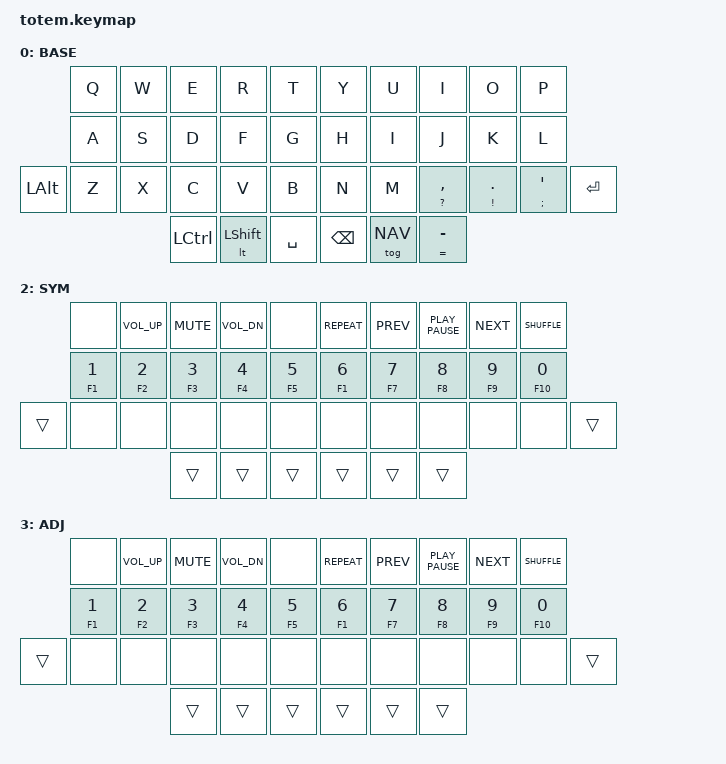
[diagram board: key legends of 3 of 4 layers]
//
//                                                        ▀▀▀▀▀     ▀▀▀▀▀          ▀▀█▀▀
//                                                        ▄▀▀▀▄  ▄  ▄▀▀▀▄  ▄  ▄▀▀▀▄  █  ▄▀▀▀▄
//                                                        █   █  █  █   █  █  █   █  █  █   █
//                                                         ▀▀▀   █   ▀▀▀   █   ▀▀▀   ▀   ▀▀▀
//                                                               █      ▄▄▄█▄▄▄    █   █  
//                                                               ▀      █  █  █     █▄█
//                                                             ▀▀▀▀▀    █  █  █      ▀
//                                                                      ▀  ▀  ▀
//
// ▄▄▄▄▄▄▄▄▄▄▄▄▄▄▄▄▄▄▄▄▄▄▄▄▄▄▄▄▄▄▄▄▄▄▄▄▄▄▄▄▄▄▄▄▄▄▄▄▄▄▄▄▄▄▄▄▄▄▄▄▄▄▄▄▄▄▄▄▄▄▄▄▄▄▄▄▄▄▄▄▄▄▄▄▄▄▄▄▄▄▄▄▄▄▄▄▄▄▄▄▄▄▄▄▄▄▄▄▄▄▄▄▄▄▄▄▄▄▄▄▄▄▄▄▄▄▄▄▄▄▄▄▄▄▄▄▄▄▄▄▄▄▄▄▄▄▄▄▄
       

#include <behaviors.dtsi>
#include <dt-bindings/zmk/keys.h>
#include <dt-bindings/zmk/bt.h>
#include <dt-bindings/zmk/outputs.h>

#define BASE 0
#define NAV  1
#define SYM  2
#define ADJ  3

&mt {
  quick-tap-ms = <100>;
  global-quick-tap;
  flavor = "tap-preferred";
  tapping-term-ms = <170>;
};

/ {
     combos {
            compatible = "zmk,combos";
            combo_esc {
                timeout-ms = <50>;
                key-positions = <0 1>;
                bindings = <&kp ESC>;
            };
            combo_tvp {
                timeout-ms = <100>;
                key-positions = <11 12 13>;
                bindings = <&tog SYM>;
            };
    };

    macros {
        gif: gif {
            label = "giphy";
            compatible = "zmk,behavior-macro";
            #binding-cells = <0>;
            bindings
                = <&macro_press &kp LSHFT>
                , <&macro_tap &kp N2>
                , <&macro_release &kp LSHFT>
                , <&macro_tap &kp G &kp I &kp F>
                ;
        };
    };

        keymap {
                compatible = "zmk,keymap";
// ▄▄▄▄▄▄▄▄▄▄▄▄▄▄▄▄▄▄▄▄▄▄▄▄▄▄▄▄▄▄▄▄▄▄▄▄▄▄▄▄▄▄▄▄▄▄▄▄▄▄▄▄▄▄▄▄▄▄▄▄▄▄▄▄▄▄▄▄▄▄▄▄▄▄▄▄▄▄▄▄▄▄▄▄▄▄▄▄▄▄▄▄▄▄▄▄▄▄▄▄▄▄▄▄▄▄▄▄▄▄▄▄▄▄▄▄▄▄▄▄▄▄▄▄▄▄▄▄▄▄▄▄▄▄▄▄▄▄▄▄▄▄▄▄▄▄▄▄▄

                base_layer {
// ┏━━━━━━━━━━━━━━━━━━━━━━━━━━━━━━━━━━━━━━━┓
label= "BASE"                              ;
// ┗━━━━━━━━━━━━━━━━━━━━━━━━━━━━━━━━━━━━━━━┛
//             ┏━━━━━━━━━━━┳━━━━━━━━━━━┳━━━━━━━━━━━┳━━━━━━━━━━━┳━━━━━━━━━━━┓   ┏━━━━━━━━━━━┳━━━━━━━━━━━┳━━━━━━━━━━━┳━━━━━━━━━━━┳━━━━━━━━━━━┓
//             ┃     Q     ┃     W     ┃     E     ┃     R     ┃     T     ┃   ┃     Y     ┃     U     ┃     I     ┃     O     ┃     P     ┃
//             ┣━━━━━━━━━━━╋━━━━━━━━━━━╋━━━━━━━━━━━╋━━━━━━━━━━━╋━━━━━━━━━━━┫   ┣━━━━━━━━━━━╋━━━━━━━━━━━╋━━━━━━━━━━━╋━━━━━━━━━━━╋━━━━━━━━━━━┫
//             ┃     A     ┃     S     ┃     D     ┃     F     ┃     G     ┃   ┃     H     ┃     I     ┃     J     ┃     K     ┃     L     ┃
// ┏━━━━━━━━━━━╋━━━━━━━━━━━╋━━━━━━━━━━━╋━━━━━━━━━━━╋━━━━━━━━━━━╋━━━━━━━━━━━┫   ┣━━━━━━━━━━━╋━━━━━━━━━━━╋━━━━━━━━━━━╋━━━━━━━━━━━╋━━━━━━━━━━━╋━━━━━━━━━━━┓
// ┃   L ALT   ┃     Z     ┃     X     ┃     C     ┃     V     ┃     B     ┃   ┃     N     ┃     M     ┃   , / ?   ┃   . / !   ┃Apos. / :   ┃   ENTER   ┃
// ┗━━━━━━━━━━━┻━━━━━━━━━━━┻━━━━━━━━━━━╋━━━━━━━━━━━╋━━━━━━━━━━━╋━━━━━━━━━━━┫   ┣━━━━━━━━━━━╋━━━━━━━━━━━╋━━━━━━━━━━━╋━━━━━━━━━━━┻━━━━━━━━━━━┻━━━━━━━━━━━┛
//                                     ┃    CTRL   ┃  L SHIFT  ┃    SPC    ┃   ┃   BSPC    ┃   L:NAV   ┃    - / =  ┃
//                                     ┗━━━━━━━━━━━┻━━━━━━━━━━━┻━━━━━━━━━━━┛   ┗━━━━━━━━━━━┻━━━━━━━━━━━┻━━━━━━━━━━━┛
 bindings = <
// ╷           ╷           ╷           ╷           ╷           ╷           ╷   ╷           ╷           ╷           ╷           ╷           ╷           ╷

                &kp Q       &kp W       &kp E       &kp R       &kp T           &kp Y       &kp U       &kp I       &kp O       &kp P
                &kp A       &kp S       &kp D       &kp F       &kp G           &kp H       &kp I       &kp J       &kp K       &kp L
    &kp LALT    &kp Z       &kp X       &kp C       &kp V       &kp B           &kp N       &kp M &mt QMARK COMMA &mt EXCL DOT &mt SEMI APOS  &kp RET
                                        &kp LCTRL   &lt LSHFT   &kp SPACE       &kp BSPC    &tog NAV    &mt EQUAL MINUS
                        >;
                };

// ▄▄▄▄▄▄▄▄▄▄▄▄▄▄▄▄▄▄▄▄▄▄▄▄▄▄▄▄▄▄▄▄▄▄▄▄▄▄▄▄▄▄▄▄▄▄▄▄▄▄▄▄▄▄▄▄▄▄▄▄▄▄▄▄▄▄▄▄▄▄▄▄▄▄▄▄▄▄▄▄▄▄▄▄▄▄▄▄▄▄▄▄▄▄▄▄▄▄▄▄▄▄▄▄▄▄▄▄▄▄▄▄▄▄▄▄▄▄▄▄▄▄▄▄▄▄▄▄▄▄▄▄▄▄▄▄▄▄▄▄▄▄▄▄▄▄▄▄▄


                nav_layer {
// ┏━━━━━━━━━━━━━━━━━━━━━━━━━━━━━━━━━━━━━━━┓
label= "NAVI"                              ;
// ┗━━━━━━━━━━━━━━━━━━━━━━━━━━━━━━━━━━━━━━━┛
//             ┏━━━━━━━━━━━┳━━━━━━━━━━━┳━━━━━━━━━━━┳━━━━━━━━━━━┳━━━━━━━━━━━┓   ┏━━━━━━━━━━━┳━━━━━━━━━━━┳━━━━━━━━━━━┳━━━━━━━━━━━┳━━━━━━━━━━━┓
//             ┃    ESC    ┃   P UP    ┃     UP    ┃   P DOWN  ┃   LBrac   ┃   ┃   RBrac   ┃     7     ┃     8     ┃     9     ┃     +     ┃
//             ┣━━━━━━━━━━━╋━━━━━━━━━━━╋━━━━━━━━━━━╋━━━━━━━━━━━╋━━━━━━━━━━━┫   ┣━━━━━━━━━━━╋━━━━━━━━━━━╋━━━━━━━━━━━╋━━━━━━━━━━━╋━━━━━━━━━━━┫
//             ┃    CAPS   ┃   LEFT    ┃    DOWN   ┃   RIGHT   ┃   LPare   ┃   ┃   RPare   ┃     4     ┃     5     ┃     6     ┃     -     ┃
// ┏━━━━━━━━━━━╋━━━━━━━━━━━╋━━━━━━━━━━━╋━━━━━━━━━━━╋━━━━━━━━━━━╋━━━━━━━━━━━┫   ┣━━━━━━━━━━━╋━━━━━━━━━━━╋━━━━━━━━━━━╋━━━━━━━━━━━╋━━━━━━━━━━━╋━━━━━━━━━━━┓
// ┃    ===    ┃    TAB    ┃           ┃           ┃     /     ┃     \     ┃   ┃     0     ┃     1     ┃     2     ┃     3     ┃     *     ┃    ===    ┃
// ┗━━━━━━━━━━━┻━━━━━━━━━━━┻━━━━━━━━━━━╋━━━━━━━━━━━╋━━━━━━━━━━━╋━━━━━━━━━━━┫   ┣━━━━━━━━━━━╋━━━━━━━━━━━╋━━━━━━━━━━━╋━━━━━━━━━━━┻━━━━━━━━━━━┻━━━━━━━━━━━┛
//                                     ┃    ===    ┃    ===    ┃    ===    ┃   ┃   ===     ┃    ===    ┃    DEL    ┃
//                                     ┗━━━━━━━━━━━┻━━━━━━━━━━━┻━━━━━━━━━━━┛   ┗━━━━━━━━━━━┻━━━━━━━━━━━┻━━━━━━━━━━━┛
 bindings = <
// ╷           ╷           ╷           ╷           ╷           ╷           ╷   ╷           ╷           ╷           ╷           ╷           ╷           ╷

                &kp ESC     &kp PG_UP   &kp UP      &kp PG_DN   &kp LBKT        &kp RBKT    &kp KP_N7   &kp KP_N8   &kp KP_N9   &kp KP_PLUS
                &kp CAPS    &kp LEFT    &kp DOWN    &kp RIGHT &mt LBRC LPAR   &kp RBRC RPAR &kp KP_N4   &kp KP_N5   &kp KP_N6   &kp KP_MINUS
    &trans      &kp TAB     &none       &none       &kp FSLH    &kp BSLH        &kp KP_N0   &kp KP_N1   &kp KP_N2   &kp KP_N3 &kp KP_MULTIPLY &trans      
                                        &trans      &trans      &trans          &trans      &trans      &DEL      
                        >;
                };

// ▄▄▄▄▄▄▄▄▄▄▄▄▄▄▄▄▄▄▄▄▄▄▄▄▄▄▄▄▄▄▄▄▄▄▄▄▄▄▄▄▄▄▄▄▄▄▄▄▄▄▄▄▄▄▄▄▄▄▄▄▄▄▄▄▄▄▄▄▄▄▄▄▄▄▄▄▄▄▄▄▄▄▄▄▄▄▄▄▄▄▄▄▄▄▄▄▄▄▄▄▄▄▄▄▄▄▄▄▄▄▄▄▄▄▄▄▄▄▄▄▄▄▄▄▄▄▄▄▄▄▄▄▄▄▄▄▄▄▄▄▄▄▄▄▄▄▄▄▄


                sim_layer {
// ┏━━━━━━━━━━━━━━━━━━━━━━━━━━━━━━━━━━━━━━━┓
label= "SYM"                               ;
// ┗━━━━━━━━━━━━━━━━━━━━━━━━━━━━━━━━━━━━━━━┛
//             ┏━━━━━━━━━━━┳━━━━━━━━━━━┳━━━━━━━━━━━┳━━━━━━━━━━━┳━━━━━━━━━━━┓   ┏━━━━━━━━━━━┳━━━━━━━━━━━┳━━━━━━━━━━━┳━━━━━━━━━━━┳━━━━━━━━━━━┓
//             ┃           ┃   VOL UP  ┃    MUTE   ┃ VOL DOWN  ┃           ┃   ┃  REPEAT   ┃   PREV    ┃ PLAY/PAU. ┃    NEXT   ┃  SHUFFLE  ┃
//             ┣━━━━━━━━━━━╋━━━━━━━━━━━╋━━━━━━━━━━━╋━━━━━━━━━━━╋━━━━━━━━━━━┫   ┣━━━━━━━━━━━╋━━━━━━━━━━━╋━━━━━━━━━━━╋━━━━━━━━━━━╋━━━━━━━━━━━┫
//             ┃   1 / F1  ┃   2 / F2  ┃   3 / F3  ┃   4 / F4  ┃   5 / F5  ┃   ┃   6 / F6  ┃   7 / F7  ┃   8 / F8  ┃   9 / F9  ┃  0 / F10  ┃
// ┏━━━━━━━━━━━╋━━━━━━━━━━━╋━━━━━━━━━━━╋━━━━━━━━━━━╋━━━━━━━━━━━╋━━━━━━━━━━━┫   ┣━━━━━━━━━━━╋━━━━━━━━━━━╋━━━━━━━━━━━╋━━━━━━━━━━━╋━━━━━━━━━━━╋━━━━━━━━━━━┓
// ┃    ===    ┃           ┃           ┃           ┃           ┃           ┃   ┃           ┃           ┃           ┃           ┃           ┃           ┃
// ┗━━━━━━━━━━━┻━━━━━━━━━━━┻━━━━━━━━━━━╋━━━━━━━━━━━╋━━━━━━━━━━━╋━━━━━━━━━━━┫   ┣━━━━━━━━━━━╋━━━━━━━━━━━╋━━━━━━━━━━━╋━━━━━━━━━━━┻━━━━━━━━━━━┻━━━━━━━━━━━┛
//                                     ┃    ===    ┃    ===    ┃    ===    ┃   ┃    ===    ┃    ===    ┃    ===    ┃
//                                     ┗━━━━━━━━━━━┻━━━━━━━━━━━┻━━━━━━━━━━━┛   ┗━━━━━━━━━━━┻━━━━━━━━━━━┻━━━━━━━━━━━┛
 bindings = <
// ╷           ╷           ╷           ╷           ╷           ╷           ╷   ╷           ╷           ╷           ╷           ╷           ╷           ╷

                &none     &kp K_VOL_UP  &kp K_MUTE &kp K_VOL_DN &none           &kp C_REPEAT       &kp K_PREV &kp K_PLAY_PAUSE &kp K_NEXT   &kp C_SHUFFLE
                &mt F1 N1   &mt F2 N2   &mt F3 N3   &mt F4 N4   &mt F5 N5       &mt F1 N6   &mt F7 N7   &mt F8 N8   &mt F9 N9   &mt F10 N0
    &trans      &none       &none       &none       &none       &none           &none       &none       &none       &none       &none       &trans        
                                        &trans      &trans      &trans          &trans      &trans      &trans    
                        >;
                };

// ▄▄▄▄▄▄▄▄▄▄▄▄▄▄▄▄▄▄▄▄▄▄▄▄▄▄▄▄▄▄▄▄▄▄▄▄▄▄▄▄▄▄▄▄▄▄▄▄▄▄▄▄▄▄▄▄▄▄▄▄▄▄▄▄▄▄▄▄▄▄▄▄▄▄▄▄▄▄▄▄▄▄▄▄▄▄▄▄▄▄▄▄▄▄▄▄▄▄▄▄▄▄▄▄▄▄▄▄▄▄▄▄▄▄▄▄▄▄▄▄▄▄▄▄▄▄▄▄▄▄▄▄▄▄▄▄▄▄▄▄▄▄▄▄▄▄▄▄▄


                adjust_layer {
// ┏━━━━━━━━━━━━━━━━━━━━━━━━━━━━━━━━━━━━━━━┓
label= "ADJ"                               ;
// ┗━━━━━━━━━━━━━━━━━━━━━━━━━━━━━━━━━━━━━━━┛
//             ┏━━━━━━━━━━━┳━━━━━━━━━━━┳━━━━━━━━━━━┳━━━━━━━━━━━┳━━━━━━━━━━━┓   ┏━━━━━━━━━━━┳━━━━━━━━━━━┳━━━━━━━━━━━┳━━━━━━━━━━━┳━━━━━━━━━━━┓
//             ┃           ┃   VOL UP  ┃    MUTE   ┃ VOL DOWN  ┃           ┃   ┃  REPEAT   ┃   PREV    ┃ PLAY/PAU. ┃    NEXT   ┃  SHUFFLE  ┃
//             ┣━━━━━━━━━━━╋━━━━━━━━━━━╋━━━━━━━━━━━╋━━━━━━━━━━━╋━━━━━━━━━━━┫   ┣━━━━━━━━━━━╋━━━━━━━━━━━╋━━━━━━━━━━━╋━━━━━━━━━━━╋━━━━━━━━━━━┫
//             ┃   1 / F1  ┃   2 / F2  ┃   3 / F3  ┃   4 / F4  ┃   5 / F5  ┃   ┃   6 / F6  ┃   7 / F7  ┃   8 / F8  ┃   9 / F9  ┃  0 / F10  ┃
// ┏━━━━━━━━━━━╋━━━━━━━━━━━╋━━━━━━━━━━━╋━━━━━━━━━━━╋━━━━━━━━━━━╋━━━━━━━━━━━┫   ┣━━━━━━━━━━━╋━━━━━━━━━━━╋━━━━━━━━━━━╋━━━━━━━━━━━╋━━━━━━━━━━━╋━━━━━━━━━━━┓
// ┃    ===    ┃           ┃           ┃           ┃           ┃           ┃   ┃           ┃           ┃           ┃           ┃           ┃           ┃
// ┗━━━━━━━━━━━┻━━━━━━━━━━━┻━━━━━━━━━━━╋━━━━━━━━━━━╋━━━━━━━━━━━╋━━━━━━━━━━━┫   ┣━━━━━━━━━━━╋━━━━━━━━━━━╋━━━━━━━━━━━╋━━━━━━━━━━━┻━━━━━━━━━━━┻━━━━━━━━━━━┛
//                                     ┃    ===    ┃    ===    ┃    ===    ┃   ┃    ===    ┃    ===    ┃    ===    ┃
//                                     ┗━━━━━━━━━━━┻━━━━━━━━━━━┻━━━━━━━━━━━┛   ┗━━━━━━━━━━━┻━━━━━━━━━━━┻━━━━━━━━━━━┛
 bindings = <
// ╷           ╷           ╷           ╷           ╷           ╷           ╷   ╷           ╷           ╷           ╷           ╷           ╷           ╷

                &none     &kp K_VOL_UP  &kp K_MUTE &kp K_VOL_DN &none           &kp C_REPEAT       &kp K_PREV &kp K_PLAY_PAUSE &kp K_NEXT   &kp C_SHUFFLE
                &mt F1 N1   &mt F2 N2   &mt F3 N3   &mt F4 N4   &mt F5 N5       &mt F1 N6   &mt F7 N7   &mt F8 N8   &mt F9 N9   &mt F10 N0
    &trans      &none       &none       &none       &none       &none           &none       &none       &none       &none       &none       &trans        
                                        &trans      &trans      &trans          &trans      &trans      &trans    
                        >;
                };
        };
};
